# 3061MNNICA register map
File version: 1.0
Registers are 32-bit, access per field, reset 0x0 unless marked. A register's access mark holds for its fields unless they carry their own. Offsets are from the block's base; [hi:lo] are bit positions; {n}, {i} and the like mark numbered series.

## IOCMG_CORE — IOCMG_CORE peripheral interface
Base 0x147F0000
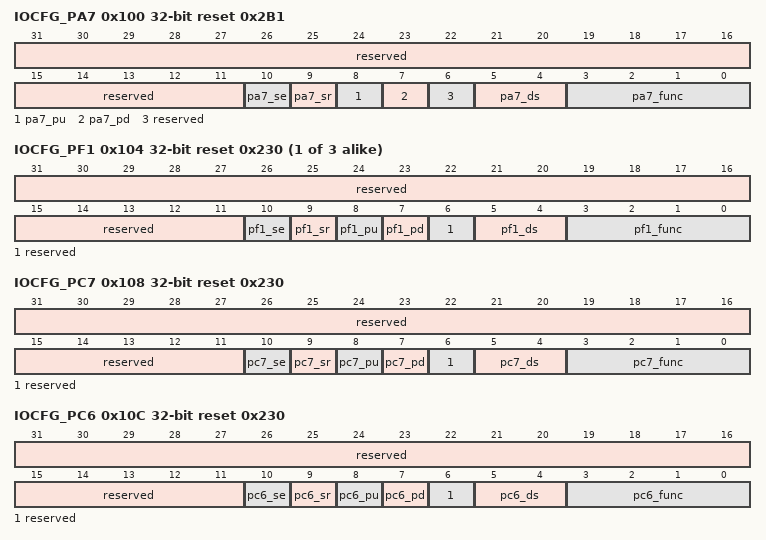
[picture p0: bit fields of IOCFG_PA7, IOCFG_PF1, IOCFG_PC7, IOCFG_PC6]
0x100 IOCFG_PA7 reset 0x2B1 — PA7管脚控制寄存器。
  [31:11] reserved ro — 保留。
  [10] pa7_se rw — 管脚施密特输入控制： 0x0：关闭； 0x1：打开。
  [9] pa7_sr rw — 管脚电平转换速率控制： 0x0：快沿输出； 0x1：慢沿输出。
  [8] pa7_pu rw — 管脚上拉控制： 0x0：关闭； 0x1：打开。
  [7] pa7_pd rw — 管脚下拉控制： 0x0：关闭； 0x1：打开。
  [6] reserved ro — 保留。
  [5:4] pa7_ds rw — 管脚驱动能力选择（档位越高，驱动能力越大）： 0x0：IO2档位4； 0x1：IO2档位3； 0x2：IO2档位2； 0x3：IO2档位1；
  [3:0] pa7_func rw — 管脚复用功能选择: 具体复用功能请参考《数据手册》。
{0xF4+0x10*i} IOCFG_PF{i} reset 0x230 (i=1..3) — PF{i}管脚控制寄存器。
  [31:11] reserved ro — 保留。
  [10] pf{i}_se rw — 管脚施密特输入控制： 0x0：关闭； 0x1：打开。
  [9] pf{i}_sr rw — 管脚电平转换速率控制： 0x0：快沿输出； 0x1：慢沿输出。
  [8] pf{i}_pu rw — 管脚上拉控制： 0x0：关闭； 0x1：打开。
  [7] pf{i}_pd rw — 管脚下拉控制： 0x0：关闭； 0x1：打开。
  [6] reserved ro — 保留。
  [5:4] pf{i}_ds rw — 管脚驱动能力选择（档位越高，驱动能力越大）： 0x0：IO2档位4； 0x1：IO2档位3； 0x2：IO2档位2； 0x3：IO2档位1；
  [3:0] pf{i}_func rw — 管脚复用功能选择: 具体复用功能请参考《数据手册》。
0x108 IOCFG_PC7 reset 0x230 — PC7管脚控制寄存器。
  [31:11] reserved ro — 保留。
  [10] pc7_se rw — 管脚施密特输入控制： 0x0：关闭； 0x1：打开。
  [9] pc7_sr rw — 管脚电平转换速率控制： 0x0：快沿输出； 0x1：慢沿输出。
  [8] pc7_pu rw — 管脚上拉控制： 0x0：关闭； 0x1：打开。
  [7] pc7_pd rw — 管脚下拉控制： 0x0：关闭； 0x1：打开。
  [6] reserved ro — 保留。
  [5:4] pc7_ds rw — 管脚驱动能力选择（档位越高，驱动能力越大）： 0x0：IO2档位4； 0x1：IO2档位3； 0x2：IO2档位2； 0x3：IO2档位1；
  [3:0] pc7_func rw — 管脚复用功能选择: 具体复用功能请参考《数据手册》。
0x10C IOCFG_PC6 reset 0x230 — PC6管脚控制寄存器。
  [31:11] reserved ro — 保留。
  [10] pc6_se rw — 管脚施密特输入控制： 0x0：关闭； 0x1：打开。
  [9] pc6_sr rw — 管脚电平转换速率控制： 0x0：快沿输出； 0x1：慢沿输出。
  [8] pc6_pu rw — 管脚上拉控制： 0x0：关闭； 0x1：打开。
  [7] pc6_pd rw — 管脚下拉控制： 0x0：关闭； 0x1：打开。
  [6] reserved ro — 保留。
  [5:4] pc6_ds rw — 管脚驱动能力选择（档位越高，驱动能力越大）： 0x0：IO2档位4； 0x1：IO2档位3； 0x2：IO2档位2； 0x3：IO2档位1；
  [3:0] pc6_func rw — 管脚复用功能选择: 具体复用功能请参考《数据手册》。
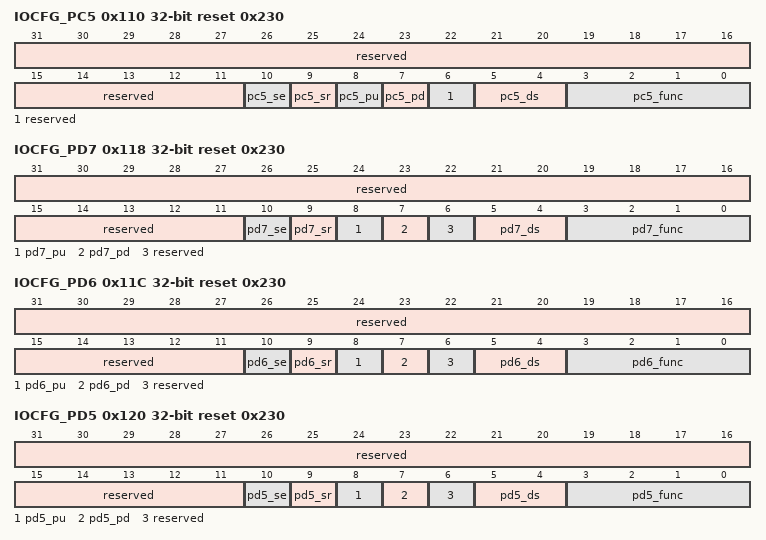
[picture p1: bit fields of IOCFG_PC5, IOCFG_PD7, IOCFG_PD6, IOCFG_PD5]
0x110 IOCFG_PC5 reset 0x230 — PC5管脚控制寄存器。
  [31:11] reserved ro — 保留。
  [10] pc5_se rw — 管脚施密特输入控制： 0x0：关闭； 0x1：打开。
  [9] pc5_sr rw — 管脚电平转换速率控制： 0x0：快沿输出； 0x1：慢沿输出。
  [8] pc5_pu rw — 管脚上拉控制： 0x0：关闭； 0x1：打开。
  [7] pc5_pd rw — 管脚下拉控制： 0x0：关闭； 0x1：打开。
  [6] reserved ro — 保留。
  [5:4] pc5_ds rw — 管脚驱动能力选择（档位越高，驱动能力越大）： 0x0：IO2档位4； 0x1：IO2档位3； 0x2：IO2档位2； 0x3：IO2档位1；
  [3:0] pc5_func rw — 管脚复用功能选择: 具体复用功能请参考《数据手册》。
0x118 IOCFG_PD7 reset 0x230 — PD7管脚控制寄存器。
  [31:11] reserved ro — 保留。
  [10] pd7_se rw — 管脚施密特输入控制： 0x0：关闭； 0x1：打开。
  [9] pd7_sr rw — 管脚电平转换速率控制： 0x0：快沿输出； 0x1：慢沿输出。
  [8] pd7_pu rw — 管脚上拉控制： 0x0：关闭； 0x1：打开。
  [7] pd7_pd rw — 管脚下拉控制： 0x0：关闭； 0x1：打开。
  [6] reserved ro — 保留。
  [5:4] pd7_ds rw — 管脚驱动能力选择（档位越高，驱动能力越大）： 0x0：IO2档位4； 0x1：IO2档位3； 0x2：IO2档位2； 0x3：IO2档位1；
  [3:0] pd7_func rw — 管脚复用功能选择: 具体复用功能请参考《数据手册》。
0x11C IOCFG_PD6 reset 0x230 — PD6管脚控制寄存器。
  [31:11] reserved ro — 保留。
  [10] pd6_se rw — 管脚施密特输入控制： 0x0：关闭； 0x1：打开。
  [9] pd6_sr rw — 管脚电平转换速率控制： 0x0：快沿输出； 0x1：慢沿输出。
  [8] pd6_pu rw — 管脚上拉控制： 0x0：关闭； 0x1：打开。
  [7] pd6_pd rw — 管脚下拉控制： 0x0：关闭； 0x1：打开。
  [6] reserved ro — 保留。
  [5:4] pd6_ds rw — 管脚驱动能力选择（档位越高，驱动能力越大）： 0x0：IO2档位4； 0x1：IO2档位3； 0x2：IO2档位2； 0x3：IO2档位1；
  [3:0] pd6_func rw — 管脚复用功能选择: 具体复用功能请参考《数据手册》。
0x120 IOCFG_PD5 reset 0x230 — PD5管脚控制寄存器。
  [31:11] reserved ro — 保留。
  [10] pd5_se rw — 管脚施密特输入控制： 0x0：关闭； 0x1：打开。
  [9] pd5_sr rw — 管脚电平转换速率控制： 0x0：快沿输出； 0x1：慢沿输出。
  [8] pd5_pu rw — 管脚上拉控制： 0x0：关闭； 0x1：打开。
  [7] pd5_pd rw — 管脚下拉控制： 0x0：关闭； 0x1：打开。
  [6] reserved ro — 保留。
  [5:4] pd5_ds rw — 管脚驱动能力选择（档位越高，驱动能力越大）： 0x0：IO2档位4； 0x1：IO2档位3； 0x2：IO2档位2； 0x3：IO2档位1；
  [3:0] pd5_func rw — 管脚复用功能选择: 具体复用功能请参考《数据手册》。
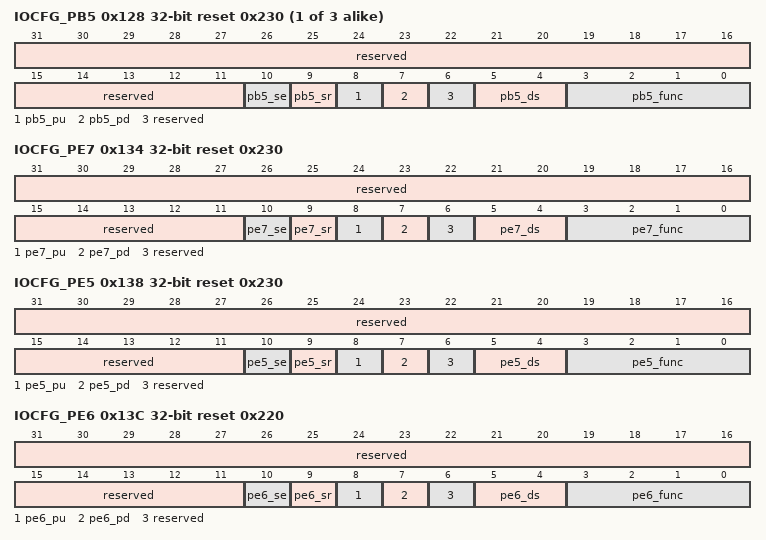
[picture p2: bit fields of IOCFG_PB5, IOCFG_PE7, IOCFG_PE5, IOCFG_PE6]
{0x114+4i} IOCFG_PB{i} reset 0x230 (i=5..7) — PB{i}管脚控制寄存器。
  [31:11] reserved ro — 保留。
  [10] pb{i}_se rw — 管脚施密特输入控制： 0x0：关闭； 0x1：打开。
  [9] pb{i}_sr rw — 管脚电平转换速率控制： 0x0：快沿输出； 0x1：慢沿输出。
  [8] pb{i}_pu rw — 管脚上拉控制： 0x0：关闭； 0x1：打开。
  [7] pb{i}_pd rw — 管脚下拉控制： 0x0：关闭； 0x1：打开。
  [6] reserved ro — 保留。
  [5:4] pb{i}_ds rw — 管脚驱动能力选择（档位越高，驱动能力越大）： 0x0：IO2档位4； 0x1：IO2档位3； 0x2：IO2档位2； 0x3：IO2档位1；
  [3:0] pb{i}_func rw — 管脚复用功能选择: 具体复用功能请参考《数据手册》。
0x134 IOCFG_PE7 reset 0x230 — PE7管脚控制寄存器。
  [31:11] reserved ro — 保留。
  [10] pe7_se rw — 管脚施密特输入控制： 0x0：关闭； 0x1：打开。
  [9] pe7_sr rw — 管脚电平转换速率控制： 0x0：快沿输出； 0x1：慢沿输出。
  [8] pe7_pu rw — 管脚上拉控制： 0x0：关闭； 0x1：打开。
  [7] pe7_pd rw — 管脚下拉控制： 0x0：关闭； 0x1：打开。
  [6] reserved ro — 保留。
  [5:4] pe7_ds rw — 管脚驱动能力选择（档位越高，驱动能力越大）： 0x0：IO2档位4； 0x1：IO2档位3； 0x2：IO2档位2； 0x3：IO2档位1；
  [3:0] pe7_func rw — 管脚复用功能选择: 具体复用功能请参考《数据手册》。
0x138 IOCFG_PE5 reset 0x230 — PE5管脚控制寄存器。
  [31:11] reserved ro — 保留。
  [10] pe5_se rw — 管脚施密特输入控制： 0x0：关闭； 0x1：打开。
  [9] pe5_sr rw — 管脚电平转换速率控制： 0x0：快沿输出； 0x1：慢沿输出。
  [8] pe5_pu rw — 管脚上拉控制： 0x0：关闭； 0x1：打开。
  [7] pe5_pd rw — 管脚下拉控制： 0x0：关闭； 0x1：打开。
  [6] reserved ro — 保留。
  [5:4] pe5_ds rw — 管脚驱动能力选择（档位越高，驱动能力越大）： 0x0：IO2档位4； 0x1：IO2档位3； 0x2：IO2档位2； 0x3：IO2档位1；
  [3:0] pe5_func rw — 管脚复用功能选择: 具体复用功能请参考《数据手册》。
0x13C IOCFG_PE6 reset 0x220 — PE6管脚控制寄存器。
  [31:11] reserved ro — 保留。
  [10] pe6_se rw — 管脚施密特输入控制： 0x0：关闭； 0x1：打开。
  [9] pe6_sr rw — 管脚电平转换速率控制： 0x0：快沿输出； 0x1：慢沿输出。
  [8] pe6_pu rw — 管脚上拉控制： 0x0：关闭； 0x1：打开。
  [7] pe6_pd rw — 管脚下拉控制： 0x0：关闭； 0x1：打开。
  [6] reserved ro — 保留。
  [5:4] pe6_ds rw — 管脚驱动能力选择（档位越高，驱动能力越大）： 0x0：IO2档位4； 0x1：IO2档位3； 0x2：IO2档位2； 0x3：IO2档位1；
  [3:0] pe6_func rw — 管脚复用功能选择: 具体复用功能请参考《数据手册》。
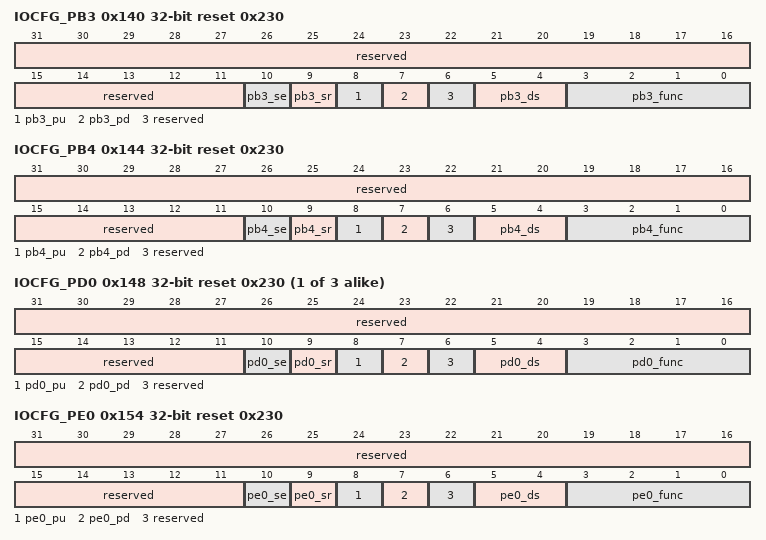
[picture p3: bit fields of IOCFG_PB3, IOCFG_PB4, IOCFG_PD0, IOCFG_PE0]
0x140 IOCFG_PB3 reset 0x230 — PB3管脚控制寄存器。
  [31:11] reserved ro — 保留。
  [10] pb3_se rw — 管脚施密特输入控制： 0x0：关闭； 0x1：打开。
  [9] pb3_sr rw — 管脚电平转换速率控制： 0x0：快沿输出； 0x1：慢沿输出。
  [8] pb3_pu rw — 管脚上拉控制： 0x0：关闭； 0x1：打开。
  [7] pb3_pd rw — 管脚下拉控制： 0x0：关闭； 0x1：打开。
  [6] reserved ro — 保留。
  [5:4] pb3_ds rw — 管脚驱动能力选择（档位越高，驱动能力越大）： 0x0：IO2档位4； 0x1：IO2档位3； 0x2：IO2档位2； 0x3：IO2档位1；
  [3:0] pb3_func rw — 管脚复用功能选择: 具体复用功能请参考《数据手册》。
0x144 IOCFG_PB4 reset 0x230 — PB4管脚控制寄存器。
  [31:11] reserved ro — 保留。
  [10] pb4_se rw — 管脚施密特输入控制： 0x0：关闭； 0x1：打开。
  [9] pb4_sr rw — 管脚电平转换速率控制： 0x0：快沿输出； 0x1：慢沿输出。
  [8] pb4_pu rw — 管脚上拉控制： 0x0：关闭； 0x1：打开。
  [7] pb4_pd rw — 管脚下拉控制： 0x0：关闭； 0x1：打开。
  [6] reserved ro — 保留。
  [5:4] pb4_ds rw — 管脚驱动能力选择（档位越高，驱动能力越大）： 0x0：IO2档位4； 0x1：IO2档位3； 0x2：IO2档位2； 0x3：IO2档位1；
  [3:0] pb4_func rw — 管脚复用功能选择: 具体复用功能请参考《数据手册》。
{0x148+4i} IOCFG_PD{i} reset 0x230 (i=0..2) — PD{i}管脚控制寄存器。
  [31:11] reserved ro — 保留。
  [10] pd{i}_se rw — 管脚施密特输入控制： 0x0：关闭； 0x1：打开。
  [9] pd{i}_sr rw — 管脚电平转换速率控制： 0x0：快沿输出； 0x1：慢沿输出。
  [8] pd{i}_pu rw — 管脚上拉控制： 0x0：关闭； 0x1：打开。
  [7] pd{i}_pd rw — 管脚下拉控制： 0x0：关闭； 0x1：打开。
  [6] reserved ro — 保留。
  [5:4] pd{i}_ds rw — 管脚驱动能力选择（档位越高，驱动能力越大）： 0x0：IO2档位4； 0x1：IO2档位3； 0x2：IO2档位2； 0x3：IO2档位1；
  [3:0] pd{i}_func rw — 管脚复用功能选择: 具体复用功能请参考《数据手册》。
0x154 IOCFG_PE0 reset 0x230 — PE0管脚控制寄存器。
  [31:11] reserved ro — 保留。
  [10] pe0_se rw — 管脚施密特输入控制： 0x0：关闭； 0x1：打开。
  [9] pe0_sr rw — 管脚电平转换速率控制： 0x0：快沿输出； 0x1：慢沿输出。
  [8] pe0_pu rw — 管脚上拉控制： 0x0：关闭； 0x1：打开。
  [7] pe0_pd rw — 管脚下拉控制： 0x0：关闭； 0x1：打开。
  [6] reserved ro — 保留。
  [5:4] pe0_ds rw — 管脚驱动能力选择（档位越高，驱动能力越大）： 0x0：IO2档位4； 0x1：IO2档位3； 0x2：IO2档位2； 0x3：IO2档位1；
  [3:0] pe0_func rw — 管脚复用功能选择: 具体复用功能请参考《数据手册》。
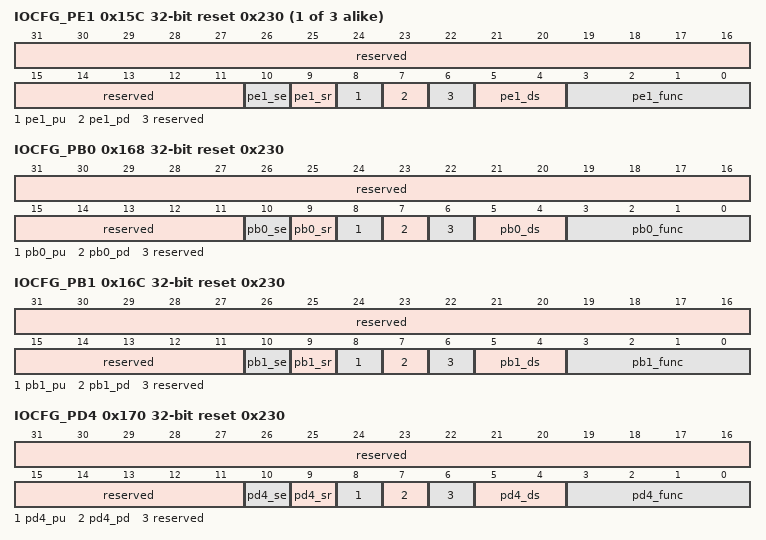
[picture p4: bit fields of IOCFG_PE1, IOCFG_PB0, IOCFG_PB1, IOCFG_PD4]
{0x158+4i} IOCFG_PE{i} reset 0x230 (i=1..3) — PE{i}管脚控制寄存器。
  [31:11] reserved ro — 保留。
  [10] pe{i}_se rw — 管脚施密特输入控制： 0x0：关闭； 0x1：打开。
  [9] pe{i}_sr rw — 管脚电平转换速率控制： 0x0：快沿输出； 0x1：慢沿输出。
  [8] pe{i}_pu rw — 管脚上拉控制： 0x0：关闭； 0x1：打开。
  [7] pe{i}_pd rw — 管脚下拉控制： 0x0：关闭； 0x1：打开。
  [6] reserved ro — 保留。
  [5:4] pe{i}_ds rw — 管脚驱动能力选择（档位越高，驱动能力越大）： 0x0：IO2档位4； 0x1：IO2档位3； 0x2：IO2档位2； 0x3：IO2档位1；
  [3:0] pe{i}_func rw — 管脚复用功能选择: 具体复用功能请参考《数据手册》。
0x168 IOCFG_PB0 reset 0x230 — PB0管脚控制寄存器。
  [31:11] reserved ro — 保留。
  [10] pb0_se rw — 管脚施密特输入控制： 0x0：关闭； 0x1：打开。
  [9] pb0_sr rw — 管脚电平转换速率控制： 0x0：快沿输出； 0x1：慢沿输出。
  [8] pb0_pu rw — 管脚上拉控制： 0x0：关闭； 0x1：打开。
  [7] pb0_pd rw — 管脚下拉控制： 0x0：关闭； 0x1：打开。
  [6] reserved ro — 保留。
  [5:4] pb0_ds rw — 管脚驱动能力选择（档位越高，驱动能力越大）： 0x0：IO2档位4； 0x1：IO2档位3； 0x2：IO2档位2； 0x3：IO2档位1；
  [3:0] pb0_func rw — 管脚复用功能选择: 具体复用功能请参考《数据手册》。
0x16C IOCFG_PB1 reset 0x230 — PB1管脚控制寄存器。
  [31:11] reserved ro — 保留。
  [10] pb1_se rw — 管脚施密特输入控制： 0x0：关闭； 0x1：打开。
  [9] pb1_sr rw — 管脚电平转换速率控制： 0x0：快沿输出； 0x1：慢沿输出。
  [8] pb1_pu rw — 管脚上拉控制： 0x0：关闭； 0x1：打开。
  [7] pb1_pd rw — 管脚下拉控制： 0x0：关闭； 0x1：打开。
  [6] reserved ro — 保留。
  [5:4] pb1_ds rw — 管脚驱动能力选择（档位越高，驱动能力越大）： 0x0：IO2档位4； 0x1：IO2档位3； 0x2：IO2档位2； 0x3：IO2档位1；
  [3:0] pb1_func rw — 管脚复用功能选择: 具体复用功能请参考《数据手册》。
0x170 IOCFG_PD4 reset 0x230 — PD4管脚控制寄存器。
  [31:11] reserved ro — 保留。
  [10] pd4_se rw — 管脚施密特输入控制： 0x0：关闭； 0x1：打开。
  [9] pd4_sr rw — 管脚电平转换速率控制： 0x0：快沿输出； 0x1：慢沿输出。
  [8] pd4_pu rw — 管脚上拉控制： 0x0：关闭； 0x1：打开。
  [7] pd4_pd rw — 管脚下拉控制： 0x0：关闭； 0x1：打开。
  [6] reserved ro — 保留。
  [5:4] pd4_ds rw — 管脚驱动能力选择（档位越高，驱动能力越大）： 0x0：IO2档位4； 0x1：IO2档位3； 0x2：IO2档位2； 0x3：IO2档位1；
  [3:0] pd4_func rw — 管脚复用功能选择: 具体复用功能请参考《数据手册》。
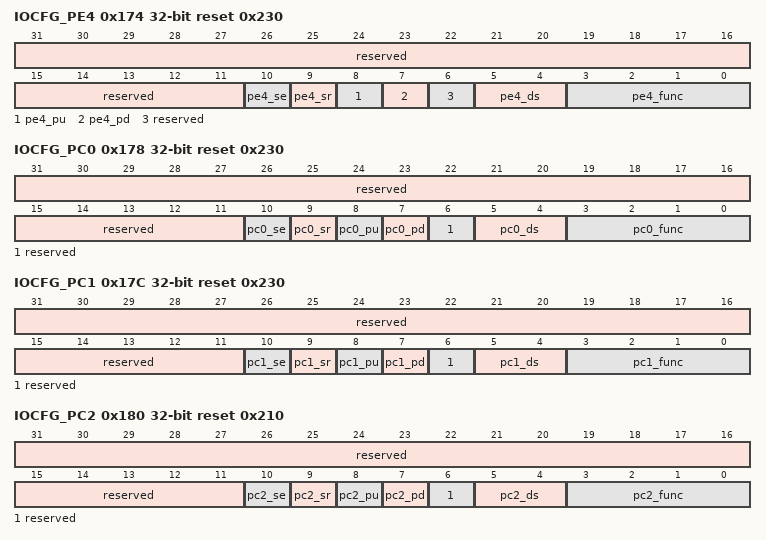
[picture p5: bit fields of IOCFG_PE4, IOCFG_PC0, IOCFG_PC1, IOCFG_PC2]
0x174 IOCFG_PE4 reset 0x230 — PE4管脚控制寄存器。
  [31:11] reserved ro — 保留。
  [10] pe4_se rw — 管脚施密特输入控制： 0x0：关闭； 0x1：打开。
  [9] pe4_sr rw — 管脚电平转换速率控制： 0x0：快沿输出； 0x1：慢沿输出。
  [8] pe4_pu rw — 管脚上拉控制： 0x0：关闭； 0x1：打开。
  [7] pe4_pd rw — 管脚下拉控制： 0x0：关闭； 0x1：打开。
  [6] reserved ro — 保留。
  [5:4] pe4_ds rw — 管脚驱动能力选择（档位越高，驱动能力越大）： 0x0：IO2档位4； 0x1：IO2档位3； 0x2：IO2档位2； 0x3：IO2档位1；
  [3:0] pe4_func rw — 管脚复用功能选择: 具体复用功能请参考《数据手册》。
0x178 IOCFG_PC0 reset 0x230 — PC0管脚控制寄存器。
  [31:11] reserved ro — 保留。
  [10] pc0_se rw — 管脚施密特输入控制： 0x0：关闭； 0x1：打开。
  [9] pc0_sr rw — 管脚电平转换速率控制： 0x0：快沿输出； 0x1：慢沿输出。
  [8] pc0_pu rw — 管脚上拉控制： 0x0：关闭； 0x1：打开。
  [7] pc0_pd rw — 管脚下拉控制： 0x0：关闭； 0x1：打开。
  [6] reserved ro — 保留。
  [5:4] pc0_ds rw — 管脚驱动能力选择（档位越高，驱动能力越大）： 0x0：IO2档位4； 0x1：IO2档位3； 0x2：IO2档位2； 0x3：IO2档位1；
  [3:0] pc0_func rw — 管脚复用功能选择: 具体复用功能请参考《数据手册》。
0x17C IOCFG_PC1 reset 0x230 — PC1管脚控制寄存器。
  [31:11] reserved ro — 保留。
  [10] pc1_se rw — 管脚施密特输入控制： 0x0：关闭； 0x1：打开。
  [9] pc1_sr rw — 管脚电平转换速率控制： 0x0：快沿输出； 0x1：慢沿输出。
  [8] pc1_pu rw — 管脚上拉控制： 0x0：关闭； 0x1：打开。
  [7] pc1_pd rw — 管脚下拉控制： 0x0：关闭； 0x1：打开。
  [6] reserved ro — 保留。
  [5:4] pc1_ds rw — 管脚驱动能力选择（档位越高，驱动能力越大）： 0x0：IO2档位4； 0x1：IO2档位3； 0x2：IO2档位2； 0x3：IO2档位1；
  [3:0] pc1_func rw — 管脚复用功能选择: 具体复用功能请参考《数据手册》。
0x180 IOCFG_PC2 reset 0x210 — PC2管脚控制寄存器。
  [31:11] reserved ro — 保留。
  [10] pc2_se rw — 管脚施密特输入控制： 0x0：关闭； 0x1：打开。
  [9] pc2_sr rw — 管脚电平转换速率控制： 0x0：快沿输出； 0x1：慢沿输出。
  [8] pc2_pu rw — 管脚上拉控制： 0x0：关闭； 0x1：打开。
  [7] pc2_pd rw — 管脚下拉控制： 0x0：关闭； 0x1：打开。
  [6] reserved ro — 保留。
  [5:4] pc2_ds rw — 管脚驱动能力选择（档位越高，驱动能力越大）： 0x0：IO2档位4； 0x1：IO2档位3； 0x2：IO2档位2； 0x3：IO2档位1；
  [3:0] pc2_func rw — 管脚复用功能选择: 具体复用功能请参考《数据手册》。
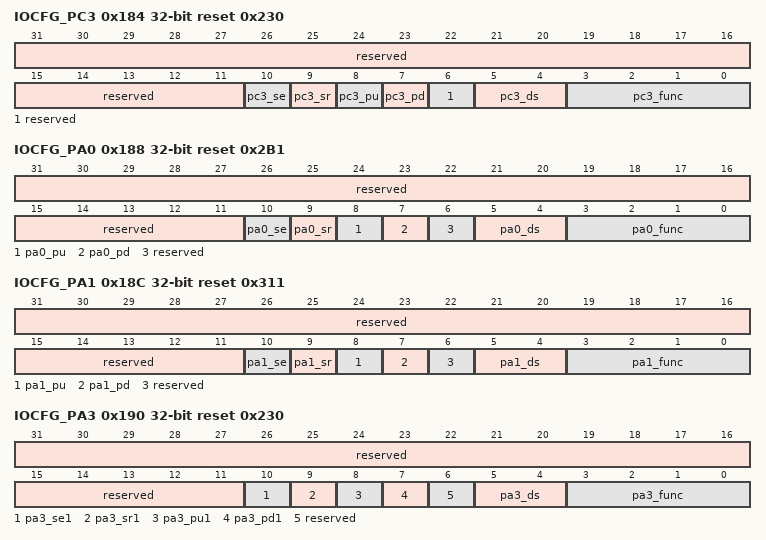
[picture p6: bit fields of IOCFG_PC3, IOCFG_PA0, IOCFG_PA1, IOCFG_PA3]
0x184 IOCFG_PC3 reset 0x230 — PC3管脚控制寄存器。
  [31:11] reserved ro — 保留。
  [10] pc3_se rw — 管脚施密特输入控制： 0x0：关闭； 0x1：打开。
  [9] pc3_sr rw — 管脚电平转换速率控制： 0x0：快沿输出； 0x1：慢沿输出。
  [8] pc3_pu rw — 管脚上拉控制： 0x0：关闭； 0x1：打开。
  [7] pc3_pd rw — 管脚下拉控制： 0x0：关闭； 0x1：打开。
  [6] reserved ro — 保留。
  [5:4] pc3_ds rw — 管脚驱动能力选择（档位越高，驱动能力越大）： 0x0：IO2档位4； 0x1：IO2档位3； 0x2：IO2档位2； 0x3：IO2档位1；
  [3:0] pc3_func rw — 管脚复用功能选择: 具体复用功能请参考《数据手册》。
0x188 IOCFG_PA0 reset 0x2B1 — PA0管脚控制寄存器。
  [31:11] reserved ro — 保留。
  [10] pa0_se rw — 管脚施密特输入控制： 0x0：关闭； 0x1：打开。
  [9] pa0_sr rw — 管脚电平转换速率控制： 0x0：快沿输出； 0x1：慢沿输出。
  [8] pa0_pu rw — 管脚上拉控制： 0x0：关闭； 0x1：打开。
  [7] pa0_pd rw — 管脚下拉控制： 0x0：关闭； 0x1：打开。
  [6] reserved ro — 保留。
  [5:4] pa0_ds rw — 管脚驱动能力选择（档位越高，驱动能力越大）： 0x0：IO2档位4； 0x1：IO2档位3； 0x2：IO2档位2； 0x3：IO2档位1；
  [3:0] pa0_func rw — 管脚复用功能选择: 具体复用功能请参考《数据手册》。
0x18C IOCFG_PA1 reset 0x311 — PA1管脚控制寄存器。
  [31:11] reserved ro — 保留。
  [10] pa1_se rw — 管脚施密特输入控制： 0x0：关闭； 0x1：打开。
  [9] pa1_sr rw — 管脚电平转换速率控制： 0x0：快沿输出； 0x1：慢沿输出。
  [8] pa1_pu rw — 管脚上拉控制： 0x0：关闭； 0x1：打开。
  [7] pa1_pd rw — 管脚下拉控制： 0x0：关闭； 0x1：打开。
  [6] reserved ro — 保留。
  [5:4] pa1_ds rw — 管脚驱动能力选择（档位越高，驱动能力越大）： 0x0：IO2档位4； 0x1：IO2档位3； 0x2：IO2档位2； 0x3：IO2档位1；
  [3:0] pa1_func rw — 管脚复用功能选择: 具体复用功能请参考《数据手册》。
0x190 IOCFG_PA3 reset 0x230 — PA3管脚控制寄存器。
  [31:11] reserved ro — 保留。
  [10] pa3_se1 rw — 管脚施密特输入控制： 0x0：关闭； 0x1：打开。
  [9] pa3_sr1 rw — 管脚电平转换速率控制： 0x0：快沿输出； 0x1：慢沿输出。
  [8] pa3_pu1 rw — 管脚上拉控制： 0x0：关闭； 0x1：打开。
  [7] pa3_pd1 rw — 管脚下拉控制： 0x0：关闭； 0x1：打开。
  [6] reserved ro — 保留。
  [5:4] pa3_ds rw — 管脚驱动能力选择（档位越高，驱动能力越大）： 0x0：IO2档位4； 0x1：IO2档位3； 0x2：IO2档位2； 0x3：IO2档位1；
  [3:0] pa3_func rw — 管脚复用功能选择: 具体复用功能请参考《数据手册》。
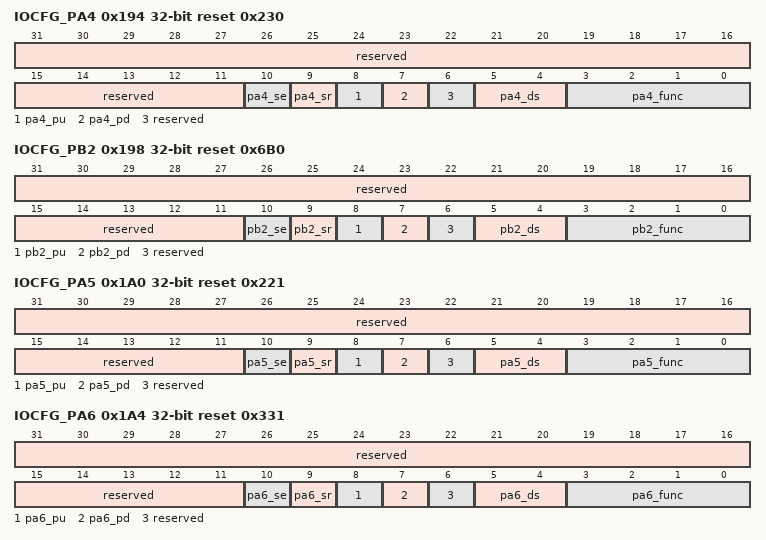
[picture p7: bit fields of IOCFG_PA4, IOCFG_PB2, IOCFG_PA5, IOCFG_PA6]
0x194 IOCFG_PA4 reset 0x230 — PA4管脚控制寄存器。
  [31:11] reserved ro — 保留。
  [10] pa4_se rw — 管脚施密特输入控制： 0x0：关闭； 0x1：打开。
  [9] pa4_sr rw — 管脚电平转换速率控制： 0x0：快沿输出； 0x1：慢沿输出。
  [8] pa4_pu rw — 管脚上拉控制： 0x0：关闭； 0x1：打开。
  [7] pa4_pd rw — 管脚下拉控制： 0x0：关闭； 0x1：打开。
  [6] reserved ro — 保留。
  [5:4] pa4_ds rw — 管脚驱动能力选择（档位越高，驱动能力越大）： 0x0：IO2档位4； 0x1：IO2档位3； 0x2：IO2档位2； 0x3：IO2档位1；
  [3:0] pa4_func rw — 管脚复用功能选择: 具体复用功能请参考《数据手册》。
0x198 IOCFG_PB2 reset 0x6B0 — PB2管脚控制寄存器。
  [31:11] reserved ro — 保留。
  [10] pb2_se rw — 管脚施密特输入控制： 0x0：关闭； 0x1：打开。
  [9] pb2_sr rw — 管脚电平转换速率控制： 0x0：快沿输出； 0x1：慢沿输出。
  [8] pb2_pu rw — 管脚上拉控制： 0x0：关闭； 0x1：打开。
  [7] pb2_pd rw — 管脚下拉控制： 0x0：关闭； 0x1：打开。
  [6] reserved ro — 保留。
  [5:4] pb2_ds rw — 管脚驱动能力选择（档位越高，驱动能力越大）： 0x0：IO2档位4； 0x1：IO2档位3； 0x2：IO2档位2； 0x3：IO2档位1；
  [3:0] pb2_func rw — 管脚复用功能选择: 具体复用功能请参考《数据手册》。
0x1A0 IOCFG_PA5 reset 0x221 — PA5管脚控制寄存器。
  [31:11] reserved ro — 保留。
  [10] pa5_se rw — 管脚施密特输入控制： 0x0：关闭； 0x1：打开。
  [9] pa5_sr rw — 管脚电平转换速率控制： 0x0：快沿输出； 0x1：慢沿输出。
  [8] pa5_pu rw — 管脚上拉控制： 0x0：关闭； 0x1：打开。
  [7] pa5_pd rw — 管脚下拉控制： 0x0：关闭； 0x1：打开。
  [6] reserved ro — 保留。
  [5:4] pa5_ds rw — 管脚驱动能力选择（档位越高，驱动能力越大）： 0x0：IO2档位4； 0x1：IO2档位3； 0x2：IO2档位2； 0x3：IO2档位1；
  [3:0] pa5_func rw — 管脚复用功能选择: 具体复用功能请参考《数据手册》。
0x1A4 IOCFG_PA6 reset 0x331 — PA6管脚控制寄存器。
  [31:11] reserved ro — 保留。
  [10] pa6_se rw — 管脚施密特输入控制： 0x0：关闭； 0x1：打开。
  [9] pa6_sr rw — 管脚电平转换速率控制： 0x0：快沿输出； 0x1：慢沿输出。
  [8] pa6_pu rw — 管脚上拉控制： 0x0：关闭； 0x1：打开。
  [7] pa6_pd rw — 管脚下拉控制： 0x0：关闭； 0x1：打开。
  [6] reserved ro — 保留。
  [5:4] pa6_ds rw — 管脚驱动能力选择（档位越高，驱动能力越大）： 0x0：IO2档位4； 0x1：IO2档位3； 0x2：IO2档位2； 0x3：IO2档位1；
  [3:0] pa6_func rw — 管脚复用功能选择: 具体复用功能请参考《数据手册》。
